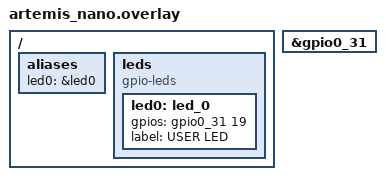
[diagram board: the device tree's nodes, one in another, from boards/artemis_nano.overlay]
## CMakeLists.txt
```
# SPDX-License-Identifier: Apache-2.0

cmake_minimum_required(VERSION 3.20.0)
find_package(Zephyr REQUIRED HINTS $ENV{ZEPHYR_BASE})
project(PhotoSignalExtractor)

target_sources(app PRIVATE src/main.c)
```

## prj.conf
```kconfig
# Enable shell subsystem
CONFIG_SHELL=y

# Enable shell history
CONFIG_SHELL_HISTORY=y

# Enable shell with UART backend
CONFIG_UART_CONSOLE=y
CONFIG_SHELL_BACKEND_SERIAL=y
CONFIG_SHELL_BACKEND_SERIAL_INIT_PRIORITY=51

# Optionally enable help for shell commands
CONFIG_SHELL_HELP=y
```

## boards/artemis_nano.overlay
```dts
/ {
    aliases {
        led0 = &led0;
    };

    leds{
        compatible = "gpio-leds";
        led0: led_0 {
            gpios = <&gpio0_31 19 GPIO_ACTIVE_HIGH>;
            label = "USER LED";
        };
    };
};

&gpio0_31 {
	status = "okay";
};
```

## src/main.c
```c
/*
 * Copyright (c) 2012-2014 Wind River Systems, Inc.
 *
 * SPDX-License-Identifier: Apache-2.0
 *
 * Simulation based on qemu_cortex_m3
 */

#include <stdio.h>

int main(void)
{
	printf("Hello World! %s\n", CONFIG_BOARD);

	return 0;
}
```

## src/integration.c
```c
#include "include/integration.h"
#include <stdio.h>

// Function to implement Trapezoidal Rule
float trapezoidal(float arr[], int n, float a, float b) {
    float h = (b - a) / n;
    float sum = arr[0] + arr[n];

    for (int i = 1; i < n; i++) {
        sum += 2 * arr[i];
    }

    return (h / 2) * sum;
}

// Function to implement Midpoint Rule
float midpoint(float arr[], int n, float a, float b) {
    float h = (b - a) / n;
    float sum = 0.0;

    for (int i = 0; i < n; i++) {
        float mid_point = (arr[i] + arr[i+1]) / 2.0;
        sum += mid_point;
    }

    return h * sum;
}

// Function to implement Simpson's Rule
float simpsons(float arr[], int n, float a, float b) {
    if (n % 2 != 0) {
        printf("n must be even for Simpson's rule\n");
        return -1;
    }

    float h = (b - a) / n;
    float sum = arr[0] + arr[n];

    for (int i = 1; i < n; i++) {
        if (i % 2 == 0) {
            sum += 2 * arr[i];
        } else {
            sum += 4 * arr[i];
        }
    }

    return (h / 3) * sum;
}
```
